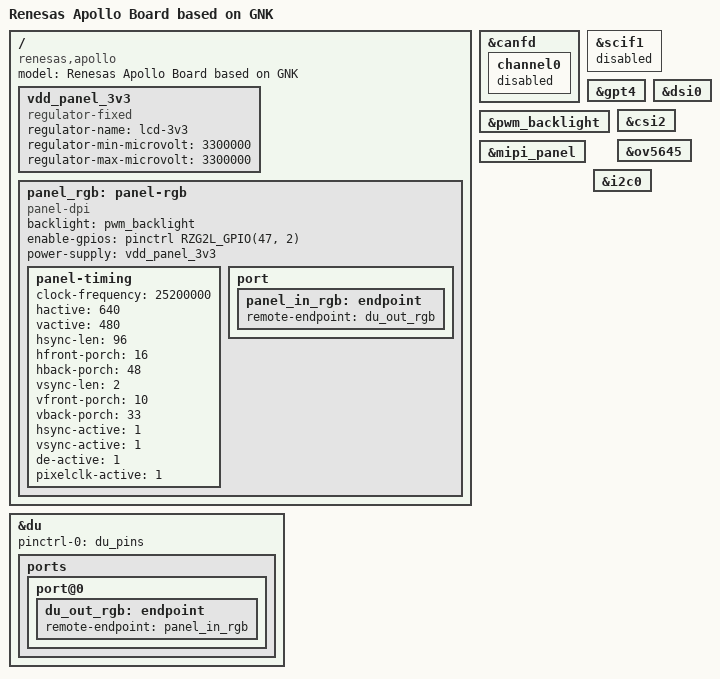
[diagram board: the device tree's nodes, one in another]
// SPDX-License-Identifier: (GPL-2.0-only OR BSD-2-Clause)
/*
 * Device Tree Source for the RZ/G2L Apollo board
 *
 * Copyright (C) 2024 Regulus Corp.
 */

/dts-v1/;
#include "r9a07g044l2.dtsi"
#include "rzg2l-smarc-som.dtsi"
#include "rzg2l-apollo-pinfunction.dtsi"
#include "rz-gnk-smarc-common.dtsi"

/*
 * ENABLE_PANEL_640_480_1024_768 == 1 : 640  x 480
 * ENABLE_PANEL_640_480_1024_768 == 0 : 1024 x 768
 */
#define ENABLE_PANEL_640_480_1024_768 1

/ {
	model = "Renesas Apollo Board based on GNK";
	compatible = "renesas,apollo", "renesas,r9a07g044l2", "renesas,r9a07g044";

	vdd_panel_3v3: vdd_panel_3v3 {
		compatible = "regulator-fixed";
		regulator-name = "lcd-3v3";
		regulator-min-microvolt = <3300000>;
		regulator-max-microvolt = <3300000>;
	};

	panel_rgb: panel-rgb {
		status = "okay";
		compatible = "panel-dpi";
		backlight = <&pwm_backlight>;
		enable-gpios = <&pinctrl RZG2L_GPIO(47, 2) GPIO_ACTIVE_HIGH>;
		power-supply = <&vdd_panel_3v3>;
		/* panel-timing is used for "panel-dpi" compatible */
		#if ENABLE_PANEL_640_480_1024_768
		panel-timing {
			clock-frequency = <25200000>;
			hactive = <640>;
			vactive = <480>;

			hsync-len = <96>;
			hfront-porch = <16>;
			hback-porch = <48>;

			vsync-len = <2>;
			vfront-porch = <10>;
			vback-porch = <33>;

			hsync-active = <1>;
			vsync-active = <1>;
			de-active = <1>;
			pixelclk-active = <1>;
		};
		#else
		panel-timing {
			clock-frequency = <70000000>;
			hactive = <1024>;
			vactive = <768>;

			hsync-len = <136>;
			hfront-porch = <24>;
			hback-porch = <160>;

			vsync-len = <6>;
			vfront-porch = <3>;
			vback-porch = <29>;

			hsync-active = <1>;
			vsync-active = <1>;
			de-active = <1>;
			pixelclk-active = <1>;
		};
		#endif
		port {
			panel_in_rgb: endpoint {
				remote-endpoint = <&du_out_rgb>;
			};
		};
	};
};

&canfd {
	channel0 {
		status = "disabled";
	};
};

&scif1 {
	status = "disabled";
};

&gpt4 {
	status = "okay";
};

&pwm_backlight {
	status = "okay";
};

&dsi0 {
	status = "okay";
};

&mipi_panel {
	status = "okay";
};

&csi2 {
	status = "okay";
};

&ov5645 {
	status = "okay";
};

&i2c0 {
	status = "okay";
};

&du {
	pinctrl-0 = <&du_pins>;
	pinctrl-names = "default";

	status = "okay";

	ports {
		port@0 {
			du_out_rgb: endpoint {
				remote-endpoint = <&panel_in_rgb>;
			};
		};
	};
};
